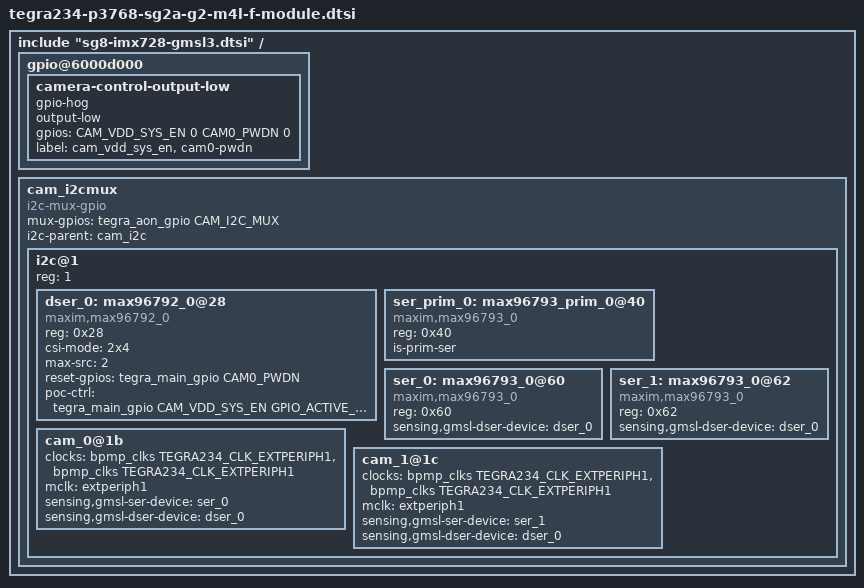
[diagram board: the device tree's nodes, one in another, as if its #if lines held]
/*
 * Copyright (c) 2018-2021, NVIDIA CORPORATION.  All rights reserved.
 *
 * This program is free software; you can redistribute it and/or modify it
 * under the terms and conditions of the GNU General Public License,
 * version 2, as published by the Free Software Foundation.
 *
 * This program is distributed in the hope it will be useful, but WITHOUT
 * ANY WARRANTY; without even the implied warranty of MERCHANTABILITY or
 * FITNESS FOR A PARTICULAR PURPOSE.  See the GNU General Public License for
 * more details.
 *
 * You should have received a copy of the GNU General Public License
 * along with this program.  If not, see <http://www.gnu.org/licenses/>.
 */

#include "dt-bindings/clock/tegra234-clock.h"

include "sg8-imx728-gmsl3.dtsi"

#define CAM_VDD_SYS_EN	TEGRA234_MAIN_GPIO(AC, 7)
#define CAM0_PWDN		TEGRA234_MAIN_GPIO(H, 6)

/* camera control gpio definitions */
/ {

	gpio@6000d000 {
		camera-control-output-low {
			gpio-hog;
			output-low;
			gpios = <CAM_VDD_SYS_EN 0 CAM0_PWDN 0>;
			label = "cam_vdd_sys_en", "cam0-pwdn";
		};
	};

	cam_i2cmux {
		compatible = "i2c-mux-gpio";
		#address-cells = <1>;
		#size-cells = <0>;
		mux-gpios = <&tegra_aon_gpio CAM_I2C_MUX GPIO_ACTIVE_HIGH>;
		i2c-parent = <&cam_i2c>;
		i2c@1 {
			reg = <1>;
			#address-cells = <1>;
			#size-cells = <0>;
			dser_0: max96792_0@28 {
				compatible = "maxim,max96792_0";
				reg = <0x28>;
				csi-mode = "2x4";
				max-src = <2>;
				reset-gpios = <&tegra_main_gpio CAM0_PWDN GPIO_ACTIVE_HIGH>;
			#if defined(SGX_YUV_GMSL1)
				poc-ctrl = <&tegra_main_gpio CAM_VDD_SYS_EN GPIO_ACTIVE_LOW>;
			#endif
			};
			ser_prim_0: max96793_prim_0@40{
				compatible = "maxim,max96793_0";
				reg = <0x40>;
				is-prim-ser;
			};
			ser_0: max96793_0@60 {
				compatible = "maxim,max96793_0";
				reg = <0x60>;
				sensing,gmsl-dser-device = <&dser_0>;
			};
			ser_1: max96793_0@62 {
				compatible = "maxim,max96793_0";
				reg = <0x62>;
				sensing,gmsl-dser-device = <&dser_0>;
			};
			cam_0@1b {
				/* Define any required hw resources needed by driver */
				/* ie. clocks, io pins, power sources */
				clocks = <&bpmp_clks TEGRA234_CLK_EXTPERIPH1>,
						<&bpmp_clks TEGRA234_CLK_EXTPERIPH1>;
				clock-names = "extperiph1", "pllp_grtba";
				mclk = "extperiph1";
				sensing,gmsl-ser-device = <&ser_0>;
				sensing,gmsl-dser-device = <&dser_0>;
			};
			cam_1@1c {
				/* Define any required hw resources needed by driver */
				/* ie. clocks, io pins, power sources */
				clocks = <&bpmp_clks TEGRA234_CLK_EXTPERIPH1>,
						<&bpmp_clks TEGRA234_CLK_EXTPERIPH1>;
				clock-names = "extperiph1", "pllp_grtba";
				mclk = "extperiph1";
				sensing,gmsl-ser-device = <&ser_1>;
				sensing,gmsl-dser-device = <&dser_0>;
			};
		};
	};
};
